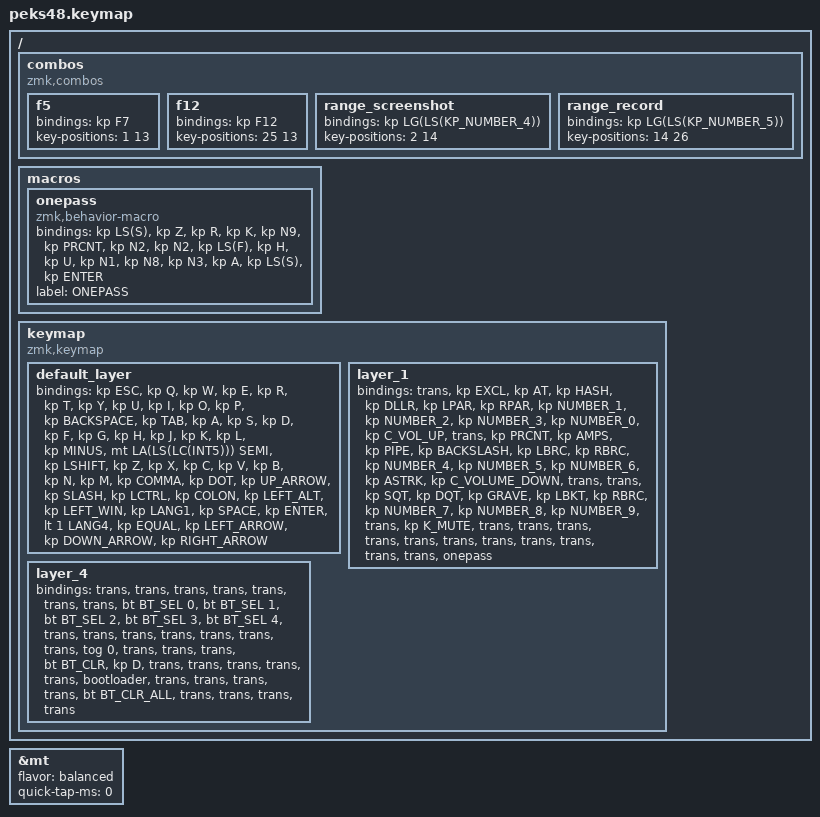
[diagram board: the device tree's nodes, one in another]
#include <input/processors.dtsi>
#include <dt-bindings/zmk/input_transform.h>
#include <zephyr/dt-bindings/input/input-event-codes.h>
#include <behaviors.dtsi>
#include <dt-bindings/zmk/bt.h>
#include <dt-bindings/zmk/keys.h>

// Conversion definition for using Japanese keyboard with OS settings

#define JP_DQUOTE       AT                // "
#define JP_AMPERSAND    CARET             // &
#define JP_QUOTE        AMPERSAND         // '
#define JP_EQUAL        UNDER             // =
#define JP_CARET        EQUAL             // ^
#define JP_YEN          0x89              // ¥
#define JP_PLUS         COLON             // +
#define JP_TILDE        PLUS              // ~
#define JP_PIPE         LS(0x89)          // |
#define JP_AT           LEFT_BRACKET      // @
#define JP_COLON        SINGLE_QUOTE      // :
#define JP_ASTERISK     DOUBLE_QUOTES     // *
#define JP_BACKQUOTE    LEFT_BRACE        // `
#define JP_UNDERSCORE   LS(0x87)          // _
#define JP_LBRACKET     RIGHT_BRACKET     // [
#define JP_RBRACKET     BACKSLASH         // ]
#define JP_LPAREN       ASTERISK          // (
#define JP_RPAREN       LEFT_PARENTHESIS  // )
#define JP_LBRACE       RIGHT_BRACE       // {
#define JP_RBRACE       PIPE              // }
#define JP_KANA         LANGUAGE_1        // かな
#define JP_EISU         LANGUAGE_2        // 英数
#define JP_HANZEN       GRAVE             // 半角/全角

&mt {
    flavor = "balanced";
    quick-tap-ms = <0>;
};

/ {
    combos {
        compatible = "zmk,combos";

        f5 {
            bindings = <&kp F7>;
            key-positions = <1 13>;
        };

        f12 {
            bindings = <&kp F12>;
            key-positions = <25 13>;
        };

        range_screenshot {
            bindings = <&kp LG(LS(KP_NUMBER_4))>;
            key-positions = <2 14>;
        };

        range_record {
            bindings = <&kp LG(LS(KP_NUMBER_5))>;
            key-positions = <14 26>;
        };
    };

    macros {
        onepass: onepass {
            compatible = "zmk,behavior-macro";
            #binding-cells = <0>;
            bindings = <&kp LS(S) &kp Z &kp R &kp K &kp N9 &kp PRCNT &kp N2 &kp N2 &kp LS(F) &kp H &kp U &kp N1 &kp N8 &kp N3 &kp A &kp LS(S) &kp ENTER>;
            label = "ONEPASS";
        };
    };

    keymap {
        compatible = "zmk,keymap";

        default_layer {
            bindings = <
&kp ESC     &kp Q      &kp W         &kp E         &kp R      &kp T        &kp Y      &kp U        &kp I      &kp O           &kp P           &kp BACKSPACE
&kp TAB     &kp A      &kp S         &kp D         &kp F      &kp G        &kp H      &kp J        &kp K      &kp L           &kp MINUS       &mt LA(LS(LC(INT5))) SEMI
&kp LSHIFT  &kp Z      &kp X         &kp C         &kp V      &kp B        &kp N      &kp M        &kp COMMA  &kp DOT         &kp UP_ARROW    &kp SLASH
&kp LCTRL   &kp COLON  &kp LEFT_ALT  &kp LEFT_WIN  &kp LANG1  &kp SPACE    &kp ENTER  &lt 1 LANG4  &kp EQUAL  &kp LEFT_ARROW  &kp DOWN_ARROW  &kp RIGHT_ARROW
            >;
        };

        layer_1 {
            bindings = <
&trans  &kp EXCL   &kp AT    &kp HASH  &kp DLLR       &kp LPAR    &kp RPAR  &kp NUMBER_1  &kp NUMBER_2  &kp NUMBER_3  &kp NUMBER_0  &kp C_VOL_UP
&trans  &kp PRCNT  &kp AMPS  &kp PIPE  &kp BACKSLASH  &kp LBRC    &kp RBRC  &kp NUMBER_4  &kp NUMBER_5  &kp NUMBER_6  &kp ASTRK     &kp C_VOLUME_DOWN
&trans  &trans     &kp SQT   &kp DQT   &kp GRAVE      &kp LBKT    &kp RBRC  &kp NUMBER_7  &kp NUMBER_8  &kp NUMBER_9  &trans        &kp K_MUTE
&trans  &trans     &trans    &trans    &trans         &trans      &trans    &trans        &trans        &trans        &trans        &onepass
            >;
        };

        layer_4 {
            bindings = <
&trans  &trans  &trans  &trans  &trans  &trans    &trans       &bt BT_SEL 0  &bt BT_SEL 1  &bt BT_SEL 2  &bt BT_SEL 3  &bt BT_SEL 4
&trans  &trans  &trans  &trans  &trans  &trans    &trans       &tog 0        &trans        &trans        &trans        &bt BT_CLR
&kp D   &trans  &trans  &trans  &trans  &trans    &bootloader  &trans        &trans        &trans        &trans        &bt BT_CLR_ALL
&trans  &trans  &trans  &trans
            >;
        };
    };
};
